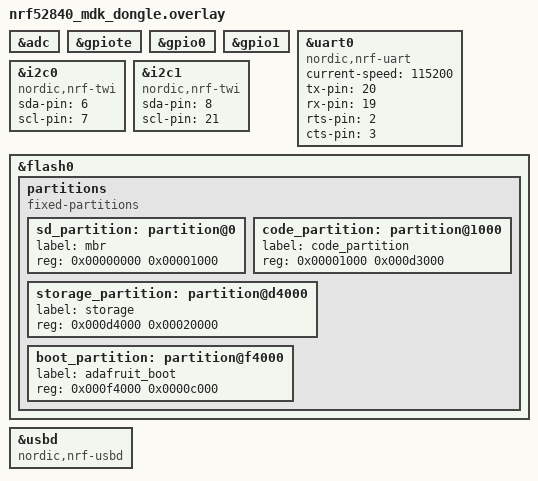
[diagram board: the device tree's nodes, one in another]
/*
 * Copyright (c) 2021 Adam BZH (bzhthedeveloper@gmail.com)
 *
 * SPDX-License-Identifier: Apache-2.0
 */


&adc {
	status = "okay";
};

&gpiote {
	status = "okay";
};

&gpio0 {
	status = "okay";
};

&gpio1 {
	status = "okay";
};

&uart0 {
	compatible = "nordic,nrf-uart";
	current-speed = <115200>;
	status = "okay";
	tx-pin = <20>;
	rx-pin = <19>;
	rts-pin = <2>;
	cts-pin = <3>;
};

&i2c0 {
	compatible = "nordic,nrf-twi";
	status = "okay";
	sda-pin = <6>;
	scl-pin = <7>;
};

&i2c1 {
	compatible = "nordic,nrf-twi";
	status = "okay";
	sda-pin = <8>;
	scl-pin = <21>;
};

&flash0 {
	/*
	 * For more information, see:
	 * http://docs.zephyrproject.org/latest/devices/dts/flash_partitions.html
	 */
	partitions {
		compatible = "fixed-partitions";
		#address-cells = <1>;
		#size-cells = <1>;

		sd_partition: partition@0 {
			label = "mbr";
			reg = <0x00000000 0x00001000>;
		};
		code_partition: partition@1000 {
			label = "code_partition";
			reg = <0x00001000 0x000d3000>;
		};

		/*
		 * The flash starting at 0x000d4000 and ending at
		 * 0x000f3fff is reserved for use by the application.
		 */

		/*
		 * Storage partition will be used by FCB/LittleFS/NVS
		 * if enabled.
		 */
		storage_partition: partition@d4000 {
			label = "storage";
			reg = <0x000d4000 0x00020000>;
		};

		boot_partition: partition@f4000 {
			label = "adafruit_boot";
			reg = <0x000f4000 0x0000c000>;
		};
	};
};

&usbd {
	compatible = "nordic,nrf-usbd";
	status = "okay";
};
